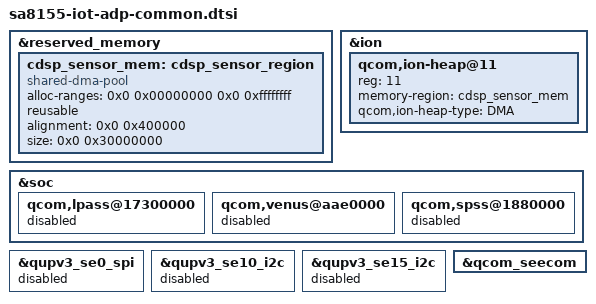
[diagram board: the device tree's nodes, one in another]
/* Copyright (c) 2021, The Linux Foundation. All rights reserved.
 *
 * This program is free software; you can redistribute it and/or modify
 * it under the terms of the GNU General Public License version 2 and
 * only version 2 as published by the Free Software Foundation.
 *
 * This program is distributed in the hope that it will be useful,
 * but WITHOUT ANY WARRANTY; without even the implied warranty of
 * MERCHANTABILITY or FITNESS FOR A PARTICULAR PURPOSE.  See the
 * GNU General Public License for more details.
 */
&reserved_memory {
	cdsp_sensor_mem: cdsp_sensor_region {
		compatible = "shared-dma-pool";
		alloc-ranges = <0x0 0x00000000 0x0 0xffffffff>;
		reusable;
		alignment = <0x0 0x400000>;
		size = <0x0 0x30000000>;
	};
};

&ion {
	qcom,ion-heap@11 {
		reg = <11>;
		memory-region = <&cdsp_sensor_mem>;
		qcom,ion-heap-type = "DMA";
	};
};

&soc {
	qcom,lpass@17300000 {
		status = "disabled";
	};

	qcom,venus@aae0000 {
		status = "disabled";
	};

	qcom,spss@1880000 {
		status = "disabled";
	};
};

&qupv3_se0_spi {
	status = "disabled";
};

&qupv3_se10_i2c {
	status = "disabled";
};

&qupv3_se15_i2c {
	status = "disabled";
};

&qcom_seecom {
	/delete-property/ qcom,appsbl-qseecom-support;
	/delete-property/ qcom,commonlib64-loaded-by-uefi;
};
